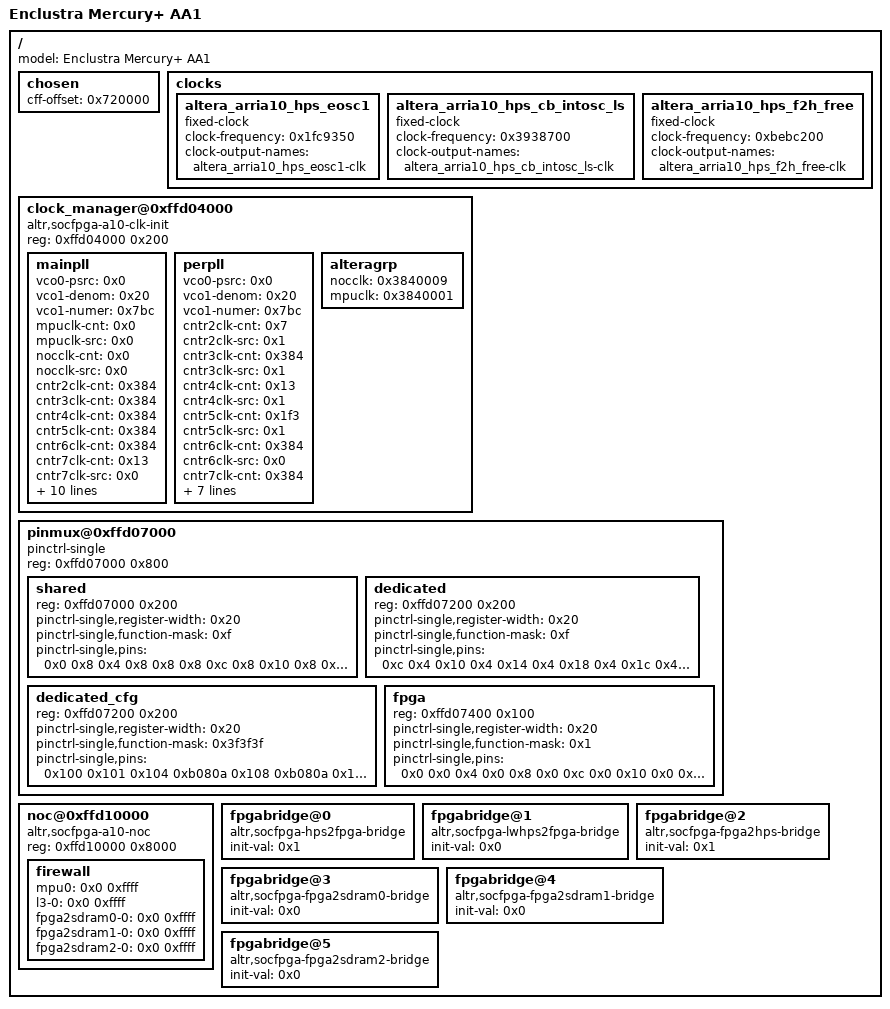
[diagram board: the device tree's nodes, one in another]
/dts-v1/;

/ {
	#address-cells = <0x1>;
	#size-cells = <0x1>;
	model = "Enclustra Mercury+ AA1";

	chosen {
		cff-offset = <0x720000>;
	};

	clocks {
		#address-cells = <0x1>;
		#size-cells = <0x1>;

		altera_arria10_hps_eosc1 {
			compatible = "fixed-clock";
			#clock-cells = <0x0>;
			clock-frequency = <0x1fc9350>;
			clock-output-names = "altera_arria10_hps_eosc1-clk";
		};

		altera_arria10_hps_cb_intosc_ls {
			compatible = "fixed-clock";
			#clock-cells = <0x0>;
			clock-frequency = <0x3938700>;
			clock-output-names = "altera_arria10_hps_cb_intosc_ls-clk";
		};

		altera_arria10_hps_f2h_free {
			compatible = "fixed-clock";
			#clock-cells = <0x0>;
			clock-frequency = <0xbebc200>;
			clock-output-names = "altera_arria10_hps_f2h_free-clk";
		};
	};

	clock_manager@0xffd04000 {
		compatible = "altr,socfpga-a10-clk-init";
		reg = <0xffd04000 0x200>;
		reg-names = "soc_clock_manager_OCP_SLV";

		mainpll {
			vco0-psrc = <0x0>;
			vco1-denom = <0x20>;
			vco1-numer = <0x7bc>;
			mpuclk-cnt = <0x0>;
			mpuclk-src = <0x0>;
			nocclk-cnt = <0x0>;
			nocclk-src = <0x0>;
			cntr2clk-cnt = <0x384>;
			cntr3clk-cnt = <0x384>;
			cntr4clk-cnt = <0x384>;
			cntr5clk-cnt = <0x384>;
			cntr6clk-cnt = <0x384>;
			cntr7clk-cnt = <0x13>;
			cntr7clk-src = <0x0>;
			cntr8clk-cnt = <0x9>;
			cntr9clk-cnt = <0x384>;
			cntr9clk-src = <0x0>;
			cntr15clk-cnt = <0x384>;
			nocdiv-l4mainclk = <0x0>;
			nocdiv-l4mpclk = <0x1>;
			nocdiv-l4spclk = <0x2>;
			nocdiv-csatclk = <0x0>;
			nocdiv-cstraceclk = <0x0>;
			nocdiv-cspdbgclk = <0x1>;
		};

		perpll {
			vco0-psrc = <0x0>;
			vco1-denom = <0x20>;
			vco1-numer = <0x7bc>;
			cntr2clk-cnt = <0x7>;
			cntr2clk-src = <0x1>;
			cntr3clk-cnt = <0x384>;
			cntr3clk-src = <0x1>;
			cntr4clk-cnt = <0x13>;
			cntr4clk-src = <0x1>;
			cntr5clk-cnt = <0x1f3>;
			cntr5clk-src = <0x1>;
			cntr6clk-cnt = <0x384>;
			cntr6clk-src = <0x0>;
			cntr7clk-cnt = <0x384>;
			cntr8clk-cnt = <0x384>;
			cntr8clk-src = <0x0>;
			cntr9clk-cnt = <0x384>;
			emacctl-emac0sel = <0x0>;
			emacctl-emac1sel = <0x0>;
			emacctl-emac2sel = <0x0>;
			gpiodiv-gpiodbclk = <0x7d00>;
		};

		alteragrp {
			nocclk = <0x3840009>;
			mpuclk = <0x3840001>;
		};
	};

	pinmux@0xffd07000 {
		#address-cells = <0x1>;
		#size-cells = <0x1>;
		compatible = "pinctrl-single";
		reg = <0xffd07000 0x800>;
		reg-names = "soc_3v_io48_pin_mux_OCP_SLV";

		shared {
			reg = <0xffd07000 0x200>;
			pinctrl-single,register-width = <0x20>;
			pinctrl-single,function-mask = <0xf>;
			pinctrl-single,pins = <0x0 0x8 0x4 0x8 0x8 0x8 0xc 0x8 0x10 0x8 0x14 0x8 0x18 0x8 0x1c 0x8 0x20 0x8 0x24 0x8 0x28 0x8 0x2c 0x8 0x30 0x4 0x34 0x4 0x38 0x4 0x3c 0x4 0x40 0x4 0x44 0x4 0x48 0x4 0x4c 0x4 0x50 0x4 0x54 0x4 0x58 0x4 0x5c 0x4 0x60 0xf 0x64 0xf 0x68 0xd 0x6c 0xd 0x70 0xf 0x74 0xf 0x78 0x0 0x7c 0x0 0x80 0xf 0x84 0xf 0x88 0x1 0x8c 0x1 0x90 0xa 0x94 0xa 0x98 0xa 0x9c 0xa 0xa0 0xa 0xa4 0xa 0xa8 0x3 0xac 0x3 0xb0 0x3 0xb4 0x3 0xb8 0xf 0xbc 0xf>;
		};

		dedicated {
			reg = <0xffd07200 0x200>;
			pinctrl-single,register-width = <0x20>;
			pinctrl-single,function-mask = <0xf>;
			pinctrl-single,pins = <0xc 0x4 0x10 0x4 0x14 0x4 0x18 0x4 0x1c 0x4 0x20 0x4 0x24 0xf 0x28 0xf 0x2c 0xa 0x30 0xa 0x34 0xa 0x38 0xa 0x3c 0xf 0x40 0xf>;
		};

		dedicated_cfg {
			reg = <0xffd07200 0x200>;
			pinctrl-single,register-width = <0x20>;
			pinctrl-single,function-mask = <0x3f3f3f>;
			pinctrl-single,pins = <0x100 0x101 0x104 0xb080a 0x108 0xb080a 0x10c 0xb080a 0x110 0x8282a 0x114 0xa282a 0x118 0x8282a 0x11c 0xa282a 0x120 0xa282a 0x124 0xa282a 0x128 0xa282a 0x12c 0xa282a 0x130 0x90000 0x134 0x90000 0x138 0x90000 0x13c 0x90000 0x140 0xa282a 0x144 0xa282a>;
		};

		fpga {
			reg = <0xffd07400 0x100>;
			pinctrl-single,register-width = <0x20>;
			pinctrl-single,function-mask = <0x1>;
			pinctrl-single,pins = <0x0 0x0 0x4 0x0 0x8 0x0 0xc 0x0 0x10 0x0 0x14 0x0 0x18 0x0 0x1c 0x0 0x20 0x0 0x24 0x0 0x28 0x0 0x2c 0x0 0x30 0x0 0x34 0x0 0x38 0x0 0x3c 0x0 0x40 0x0>;
		};
	};

	noc@0xffd10000 {
		compatible = "altr,socfpga-a10-noc";
		reg = <0xffd10000 0x8000>;
		reg-names = "mpu_m0";

		firewall {
			mpu0 = <0x0 0xffff>;
			l3-0 = <0x0 0xffff>;
			fpga2sdram0-0 = <0x0 0xffff>;
			fpga2sdram1-0 = <0x0 0xffff>;
			fpga2sdram2-0 = <0x0 0xffff>;
		};
	};

	fpgabridge@0 {
		compatible = "altr,socfpga-hps2fpga-bridge";
		init-val = <0x1>;
	};

	fpgabridge@1 {
		compatible = "altr,socfpga-lwhps2fpga-bridge";
		init-val = <0x0>;
	};

	fpgabridge@2 {
		compatible = "altr,socfpga-fpga2hps-bridge";
		init-val = <0x1>;
	};

	fpgabridge@3 {
		compatible = "altr,socfpga-fpga2sdram0-bridge";
		init-val = <0x0>;
	};

	fpgabridge@4 {
		compatible = "altr,socfpga-fpga2sdram1-bridge";
		init-val = <0x0>;
	};

	fpgabridge@5 {
		compatible = "altr,socfpga-fpga2sdram2-bridge";
		init-val = <0x0>;
	};
};
